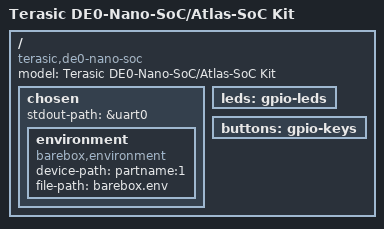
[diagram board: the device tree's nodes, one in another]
/*
 *  Copyright (C) 2013 Steffen Trumtrar <s.trumtrar@pengutronix.de>
 *
 * This program is free software; you can redistribute it and/or modify
 * it under the terms of the GNU General Public License as published by
 * the Free Software Foundation; either version 2 of the License, or
 * (at your option) any later version.
 *
 * This program is distributed in the hope that it will be useful,
 * but WITHOUT ANY WARRANTY; without even the implied warranty of
 * MERCHANTABILITY or FITNESS FOR A PARTICULAR PURPOSE.  See the
 * GNU General Public License for more details.
 *
 * You should have received a copy of the GNU General Public License
 * along with this program.  If not, see <http://www.gnu.org/licenses/>.
 */

#include <arm/socfpga_cyclone5_de0_sockit.dts>
#include "socfpga.dtsi"

/ {
	model = "Terasic DE0-Nano-SoC/Atlas-SoC Kit";
	compatible = "terasic,de0-nano-soc","altr,socfpga-cyclone5", "altr,socfpga";

	chosen {
		stdout-path = &uart0;

		environment {
			compatible = "barebox,environment";
			device-path = &mmc, "partname:1";
			file-path = "barebox.env";
		};
	};

	leds: gpio-leds {
	};

	buttons: gpio-keys {
	};
};
